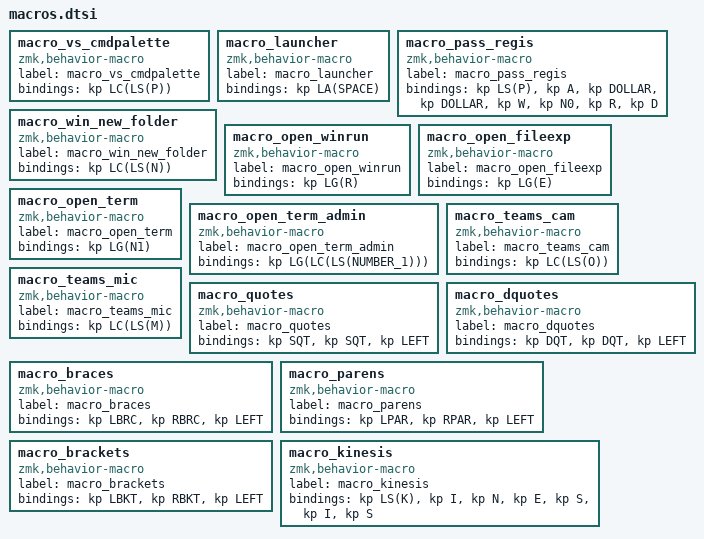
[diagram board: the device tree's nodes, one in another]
macro_vs_cmdpalette: macro_vs_cmdpalette{
compatible = "zmk,behavior-macro";
label = "macro_vs_cmdpalette";
#binding-cells = <0>;
bindings = <&kp LC(LS(P))>;
};
macro_launcher: macro_launcher{
compatible = "zmk,behavior-macro";
label = "macro_launcher";
#binding-cells = <0>;
bindings = <&kp LA(SPACE)>;
};
macro_pass_regis: macro_pass_regis{
compatible = "zmk,behavior-macro";
label = "macro_pass_regis";
#binding-cells = <0>;
bindings = <&kp LS(P)>, <&kp A>, <&kp DOLLAR>, <&kp DOLLAR>, <&kp W>, <&kp N0>, <&kp R>, <&kp D>;
};
macro_win_new_folder: macro_win_new_folder{
compatible = "zmk,behavior-macro";
label = "macro_win_new_folder";
#binding-cells = <0>;
bindings = <&kp LC(LS(N))>;
};
macro_open_winrun: macro_open_winrun{
compatible = "zmk,behavior-macro";
label = "macro_open_winrun";
#binding-cells = <0>;
bindings = <&kp LG(R)>;
};
macro_open_fileexp: macro_open_fileexp{
compatible = "zmk,behavior-macro";
label = "macro_open_fileexp";
#binding-cells = <0>;
bindings = <&kp LG(E)>;
};
macro_open_term: macro_open_term{
compatible = "zmk,behavior-macro";
label = "macro_open_term";
#binding-cells = <0>;
bindings = <&kp LG(N1)>;
};
macro_open_term_admin: macro_open_term_admin{
compatible = "zmk,behavior-macro";
label = "macro_open_term_admin";
#binding-cells = <0>;
bindings = <&kp LG(LC(LS(NUMBER_1)))>;
};
macro_teams_cam: macro_teams_cam{
compatible = "zmk,behavior-macro";
label = "macro_teams_cam";
#binding-cells = <0>;
bindings = <&kp LC(LS(O))>;
};
macro_teams_mic: macro_teams_mic{
compatible = "zmk,behavior-macro";
label = "macro_teams_mic";
#binding-cells = <0>;
bindings = <&kp LC(LS(M))>;
};
macro_quotes: macro_quotes{
compatible = "zmk,behavior-macro";
label = "macro_quotes";
#binding-cells = <0>;
bindings = <&kp SQT>, <&kp SQT>, <&kp LEFT>;
};
macro_dquotes: macro_dquotes{
compatible = "zmk,behavior-macro";
label = "macro_dquotes";
#binding-cells = <0>;
bindings = <&kp DQT>, <&kp DQT>, <&kp LEFT>;
};
macro_braces: macro_braces{
compatible = "zmk,behavior-macro";
label = "macro_braces";
#binding-cells = <0>;
bindings = <&kp LBRC>, <&kp RBRC>, <&kp LEFT>;
};
macro_parens: macro_parens{
compatible = "zmk,behavior-macro";
label = "macro_parens";
#binding-cells = <0>;
bindings = <&kp LPAR>, <&kp RPAR>, <&kp LEFT>;
};
macro_brackets: macro_brackets{
compatible = "zmk,behavior-macro";
label = "macro_brackets";
#binding-cells = <0>;
bindings = <&kp LBKT>, <&kp RBKT>, <&kp LEFT>;
};
macro_kinesis: macro_kinesis{
compatible = "zmk,behavior-macro";
label = "macro_kinesis";
#binding-cells = <0>;
bindings = <&kp LS(K)>, <&kp I>, <&kp N>, <&kp E>, <&kp S>, <&kp I>, <&kp S>;
};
